AUTOSAR XML (schema 00048)
package /HuaweiMDC/FunctionalSoftware/FusionApplication/Execution
  executable FusionExecutable
    root sw component prototype FusionRootSwComponent: application-type=FusionApplicationSwComponent
package /HuaweiMDC/FunctionalSoftware/FusionApplication/SwComponent
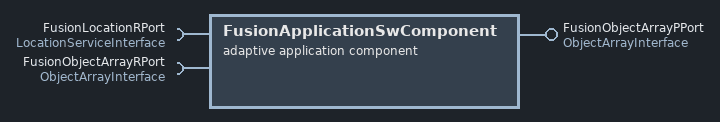
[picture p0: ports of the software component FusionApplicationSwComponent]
  adaptive application sw component type FusionApplicationSwComponent
    require port FusionLocationRPort: required-interface=LocationServiceInterface
    provide port FusionObjectArrayPPort: provided-interface=ObjectArrayInterface
    require port FusionObjectArrayRPort: required-interface=ObjectArrayInterface
